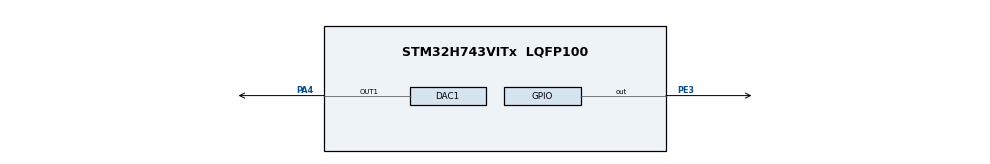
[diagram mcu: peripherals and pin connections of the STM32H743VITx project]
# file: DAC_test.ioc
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DAC1.DAC_Channel-DAC_OUT1=DAC_CHANNEL_1
DAC1.DAC_Trigger-DAC_OUT1=DAC_TRIGGER_T7_TRGO
Dma.DAC1_CH1.0.Direction=DMA_MEMORY_TO_PERIPH
Dma.DAC1_CH1.0.EventEnable=DISABLE
Dma.DAC1_CH1.0.FIFOMode=DMA_FIFOMODE_DISABLE
Dma.DAC1_CH1.0.Instance=DMA1_Stream0
Dma.DAC1_CH1.0.MemDataAlignment=DMA_MDATAALIGN_HALFWORD
Dma.DAC1_CH1.0.MemInc=DMA_MINC_ENABLE
Dma.DAC1_CH1.0.Mode=DMA_CIRCULAR
Dma.DAC1_CH1.0.PeriphDataAlignment=DMA_PDATAALIGN_HALFWORD
Dma.DAC1_CH1.0.PeriphInc=DMA_PINC_DISABLE
Dma.DAC1_CH1.0.Polarity=HAL_DMAMUX_REQ_GEN_RISING
Dma.DAC1_CH1.0.Priority=DMA_PRIORITY_MEDIUM
Dma.DAC1_CH1.0.RequestNumber=1
Dma.DAC1_CH1.0.SignalID=NONE
Dma.DAC1_CH1.0.SyncEnable=DISABLE
Dma.DAC1_CH1.0.SyncPolarity=HAL_DMAMUX_SYNC_NO_EVENT
Dma.DAC1_CH1.0.SyncRequestNumber=1
Dma.DAC1_CH1.0.SyncSignalID=NONE
Dma.Request0=DAC1_CH1
Mcu.Family=STM32H7
Mcu.Name=STM32H743VITx
Mcu.Package=LQFP100
NVIC.DMA1_Stream0_IRQn=true\:0\:0\:false\:false\:true\:false\:true\:true
NVIC.PriorityGroup=NVIC_PRIORITYGROUP_4
PA13\ (JTMS/SWDIO).Mode=Serial_Wire
PA13\ (JTMS/SWDIO).Signal=DEBUG_JTMS-SWDIO
PA14\ (JTCK/SWCLK).Mode=Serial_Wire
PA14\ (JTCK/SWCLK).Signal=DEBUG_JTCK-SWCLK
PA4.Signal=COMP_DAC11_group
PE3.Signal=GPIO_Output
PH0-OSC_IN\ (PH0).Mode=HSE-External-Oscillator
PH0-OSC_IN\ (PH0).Signal=RCC_OSC_IN
PH1-OSC_OUT\ (PH1).Mode=HSE-External-Oscillator
PH1-OSC_OUT\ (PH1).Signal=RCC_OSC_OUT
ProjectManager.HeapSize=0x200
ProjectManager.StackSize=0x400
ProjectManager.TargetToolchain=STM32CubeIDE
RCC.ADCFreq_Value=50390625
RCC.APB1Freq_Value=100000000
RCC.APB2Freq_Value=100000000
RCC.APB3Freq_Value=100000000
RCC.APB4Freq_Value=100000000
RCC.CortexFreq_Value=100000000
RCC.DIVM1=5
RCC.DIVN1=40
RCC.HCLKFreq_Value=100000000
RCC.PLLSourceVirtual=RCC_PLLSOURCE_HSE
RCC.SYSCLKFreq_VALUE=100000000
RCC.SYSCLKSource=RCC_SYSCLKSOURCE_PLLCLK
RCC.USBFreq_Value=100000000
SH.COMP_DAC11_group.0=DAC1_OUT1,DAC_OUT1
TIM7.Period=9999
TIM7.Prescaler=9999
TIM7.TIM_MasterOutputTrigger=TIM_TRGO_UPDATE
VP_TIM7_VS_ClockSourceINT.Mode=Enable_Timer
board=custom

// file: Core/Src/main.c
/* USER CODE BEGIN Header */
/**
  ******************************************************************************
  * @file           : main.c
  * @brief          : Main program body
  ******************************************************************************
  * @attention
  *
  * Copyright (c) 2026 STMicroelectronics.
  * All rights reserved.
  *
  * This software is licensed under terms that can be found in the LICENSE file
  * in the root directory of this software component.
  * If no LICENSE file comes with this software, it is provided AS-IS.
  *
  ******************************************************************************
  */
/* USER CODE END Header */
#include "main.h"
#include "dac.h"
#include "dma.h"
#include "tim.h"
#include "gpio.h"

/* USER CODE BEGIN PD */
#define DAC_BUFFER_SIZE 256
/* USER CODE END PD */

/* USER CODE BEGIN PV */
uint32_t DAC_in;
uint32_t SawDac;
float SawAmpVol = 1.5;
float OffsetVol = 1.0;
uint32_t SawPeriodMs;    // Период пилы в миллисекундах
uint32_t SawAmpDac;
uint32_t OffsetDac;

volatile uint16_t dac_buffer[DAC_BUFFER_SIZE];
/* USER CODE END PV */

void SystemClock_Config(void);
/* USER CODE BEGIN PFP */
void CalculateSawtoothBuffer(void);
void UpdateSawtooth(float , float , float );

//                HAL_GPIO_TogglePin(GPIOE, GPIO_PIN_3);
//                SawDac +=1;
//                SawDac = (SawDac % SawAmpDac);
//                if(SawDac>=SawAmpDac){DAC_in = SawAmpDac;}
/* USER CODE END PFP */

int main(void)
{

  /* MCU Configuration--------------------------------------------------------*/

  /* Reset of all peripherals, Initializes the Flash interface and the Systick. */
  HAL_Init();

  /* Configure the system clock */
  SystemClock_Config();

  /* Initialize all configured peripherals */
  MX_GPIO_Init();
  MX_DMA_Init();
  MX_DAC1_Init();
  MX_TIM7_Init();
  /* USER CODE BEGIN 2 */

//  HAL_TIM_Base_Start_IT(&htim7);// прерывание по update
  DAC_in = 0;
  SawDac = 0;
  CalculateSawtoothBuffer();
  UpdateSawtooth(1.5,1.5,15);
  HAL_DAC_Start_DMA(&hdac1, DAC_CHANNEL_1,(uint32_t*)dac_buffer,DAC_BUFFER_SIZE,DAC_ALIGN_12B_R);
  HAL_TIM_Base_Start(&htim7);

//  __HAL_TIM_SET_PRESCALER(&htim7,99);
//  __HAL_TIM_SET_AUTORELOAD(&htim7,99);

  /* USER CODE END 2 */

  /* Infinite loop */
  while (1)
  {

    /* USER CODE BEGIN 3 */
//	  HAL_DAC_SetValue(&hdac1,DAC_CHANNEL_1,DAC_ALIGN_12B_R,DAC_in);
//      HAL_Delay(2);
//      DAC_in = SawDac + 1365;
  }
  /* USER CODE END 3 */
}

void SystemClock_Config(void)
{
  RCC_OscInitTypeDef RCC_OscInitStruct = {0};
  RCC_ClkInitTypeDef RCC_ClkInitStruct = {0};

  /** Supply configuration update enable
  */
  HAL_PWREx_ConfigSupply(PWR_LDO_SUPPLY);

  /** Configure the main internal regulator output voltage
  */
  __HAL_PWR_VOLTAGESCALING_CONFIG(PWR_REGULATOR_VOLTAGE_SCALE3);

  while(!__HAL_PWR_GET_FLAG(PWR_FLAG_VOSRDY)) {}

  /** Initializes the RCC Oscillators according to the specified parameters
  * in the RCC_OscInitTypeDef structure.
  */
  RCC_OscInitStruct.OscillatorType = RCC_OSCILLATORTYPE_HSE;
  RCC_OscInitStruct.HSEState = RCC_HSE_ON;
  RCC_OscInitStruct.PLL.PLLState = RCC_PLL_ON;
  RCC_OscInitStruct.PLL.PLLSource = RCC_PLLSOURCE_HSE;
  RCC_OscInitStruct.PLL.PLLM = 5;
  RCC_OscInitStruct.PLL.PLLN = 40;
  RCC_OscInitStruct.PLL.PLLP = 2;
  RCC_OscInitStruct.PLL.PLLQ = 2;
  RCC_OscInitStruct.PLL.PLLR = 2;
  RCC_OscInitStruct.PLL.PLLRGE = RCC_PLL1VCIRANGE_2;
  RCC_OscInitStruct.PLL.PLLVCOSEL = RCC_PLL1VCOWIDE;
  RCC_OscInitStruct.PLL.PLLFRACN = 0;
  if (HAL_RCC_OscConfig(&RCC_OscInitStruct) != HAL_OK)
  {
    Error_Handler();
  }

  /** Initializes the CPU, AHB and APB buses clocks
  */
  RCC_ClkInitStruct.ClockType = RCC_CLOCKTYPE_HCLK|RCC_CLOCKTYPE_SYSCLK
                              |RCC_CLOCKTYPE_PCLK1|RCC_CLOCKTYPE_PCLK2
                              |RCC_CLOCKTYPE_D3PCLK1|RCC_CLOCKTYPE_D1PCLK1;
  RCC_ClkInitStruct.SYSCLKSource = RCC_SYSCLKSOURCE_PLLCLK;
  RCC_ClkInitStruct.SYSCLKDivider = RCC_SYSCLK_DIV1;
  RCC_ClkInitStruct.AHBCLKDivider = RCC_HCLK_DIV1;
  RCC_ClkInitStruct.APB3CLKDivider = RCC_APB3_DIV1;
  RCC_ClkInitStruct.APB1CLKDivider = RCC_APB1_DIV1;
  RCC_ClkInitStruct.APB2CLKDivider = RCC_APB2_DIV1;
  RCC_ClkInitStruct.APB4CLKDivider = RCC_APB4_DIV1;

  if (HAL_RCC_ClockConfig(&RCC_ClkInitStruct, FLASH_LATENCY_2) != HAL_OK)
  {
    Error_Handler();
  }
}

/* USER CODE BEGIN 4 */
void CalculateSawtoothBuffer(void)
{
    for (int i = 0; i < DAC_BUFFER_SIZE; i++) {
        // Линейное нара�?тание от 0 до SawAmpDac
        uint32_t value = (i * SawAmpDac) / (DAC_BUFFER_SIZE - 1);
        value += OffsetDac;

        // Ограничение
        if (value > 4095) value = 4095;
        if (value < 0) value = 0;

        dac_buffer[i] = (uint16_t)value;
    }
}

// Функция обновления параметров пилы
void UpdateSawtooth(float amplitude_volts, float offset_volts, float period_ms)
{
    // Конвертация вольт в коды DAC (Vref = 3.3V)
    SawAmpDac = (uint32_t)(amplitude_volts * 4095.0f / 3.3f);
    OffsetDac = (uint32_t)(offset_volts * 4095.0f / 3.3f);
    SawPeriodMs = (uint32_t)period_ms;

    // Пересчитать частоту таймера
    // Частота DAC обновления = DAC_BUFFER_SIZE / (period_ms / 1000)
    uint32_t dac_freq_hz = (DAC_BUFFER_SIZE * 1000) / SawPeriodMs;

    // Настройка таймера (TIM7) для нужной частоты
    // При APB1 = 100 МГц
    uint32_t timer_clock = 100000000;  // 100 МГц
    uint32_t prescaler = 0;
    uint32_t period = 0;

    // Подбор делителей
    uint32_t total_divider = timer_clock / dac_freq_hz;

    // Если делитель небольшой, то prescaler = 0
    if (total_divider <= 65536) {
        prescaler = 0;
        period = total_divider - 1;
    }
    // Если делитель больше 65536, нужно использовать prescaler
    else {
        // Ищем prescaler такой, чтобы period не превышал 65535
        prescaler = total_divider / 65536;
        period = (total_divider / (prescaler + 1)) - 1;
    }
    __HAL_TIM_SET_PRESCALER(&htim7, prescaler);
    __HAL_TIM_SET_AUTORELOAD(&htim7, period);

    // Пересчитать буфер
    CalculateSawtoothBuffer();
}
/* USER CODE END 4 */

void Error_Handler(void)
{
  __disable_irq();
  while (1)
  {
  }
}
